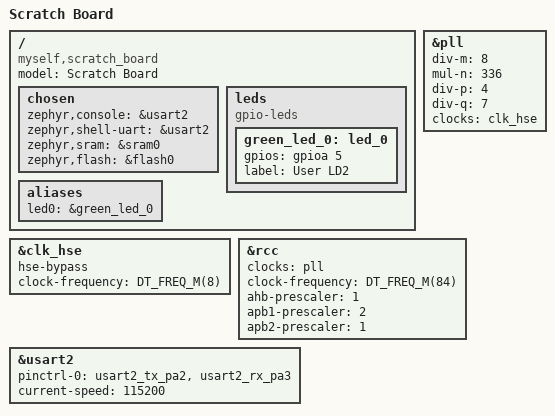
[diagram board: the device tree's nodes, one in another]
/dts-v1/;
#include <st/f4/stm32f401Xe.dtsi>
#include <st/f4/stm32f401r(d-e)tx-pinctrl.dtsi>

/ {
	model = "Scratch Board";
	compatible = "myself,scratch_board";

	chosen {
		zephyr,console = &usart2;
		zephyr,shell-uart = &usart2;
		zephyr,sram = &sram0;
		zephyr,flash = &flash0;
	};

	leds {
		compatible = "gpio-leds";
		green_led_0: led_0 {
			gpios = <&gpioa 5 GPIO_ACTIVE_HIGH>;
			label = "User LD2";
		};
	};

	aliases {
		led0 = &green_led_0;
	};
};

&clk_hse {
	hse-bypass;
	clock-frequency = <DT_FREQ_M(8)>;
	status = "okay";
};

&pll {
	div-m = <8>;
	mul-n = <336>;
	div-p = <4>;
	div-q = <7>;
	clocks = <&clk_hse>;
	status = "okay";
};

&rcc {
	clocks = <&pll>;
	clock-frequency = <DT_FREQ_M(84)>;
	ahb-prescaler = <1>;
	apb1-prescaler = <2>;
	apb2-prescaler = <1>;
};

&usart2 {
	pinctrl-0 = <&usart2_tx_pa2 &usart2_rx_pa3>;
	pinctrl-names = "default";
	current-speed = <115200>;
	status = "okay";
};
